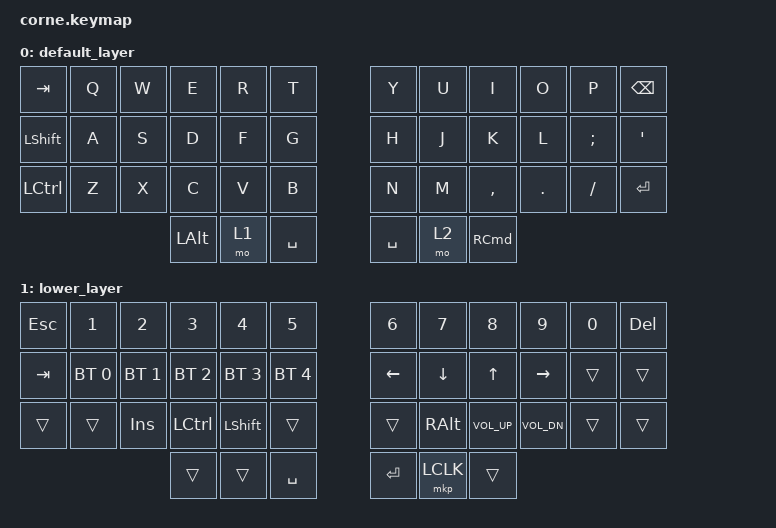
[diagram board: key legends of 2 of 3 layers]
        /*
 * Copyright (c) 2020 The ZMK Contributors
 *
 * SPDX-License-Identifier: MIT
 */

#include <dt-bindings/zmk/mouse.h>
#include <behaviors.dtsi>
#include <dt-bindings/zmk/keys.h>
#include <dt-bindings/zmk/bt.h>

/ {
        keymap {
                compatible = "zmk,keymap";

                default_layer {
                   bindings = <
// ╭─────────────────────┬─────────────────────┬────────────────────┬─────────────────────┬────────────────────┬─────────────────────╮                    ╭─────────────────────┬─────────────────────┬───────────────────┬─────────────────────┬──────────────────┬──────────────────────╮
// |        TAB          |         Q           |         W          |           E         |         R          |          T          |                    |          Y          |          U          |         I         |          O          |        P         |         BKSP         |
           &kp TAB               &kp Q                 &kp W                  &kp E               &kp R                 &kp T                                      &kp Y                 &kp U                &kp I                &kp O               &kp P               &kp BSPC
// ├─────────────────────┼─────────────────────┼────────────────────┼─────────────────────┼────────────────────┼─────────────────────┤                    ├─────────────────────┼─────────────────────┼───────────────────┼─────────────────────┼──────────────────┼──────────────────────┤
// |        SHFT         |          A          |          S         |          D          |         F          |          G          |                    |         H           |         J           |         K         |          L          |        ;         |         '            |
         &kp LSHFT               &kp A                 &kp S                 &kp D                &kp F                 &kp G                                      &kp H                 &kp J                 &kp K               &kp L              &kp SEMI             &kp SQT  
// ├─────────────────────┼─────────────────────┼────────────────────┼─────────────────────┼────────────────────┼─────────────────────┤                    ├─────────────────────┼─────────────────────┼───────────────────┼─────────────────────┼──────────────────┼──────────────────────┤
// |         CTRL        |         Z           |         X          |          C          |          V         |          B          |                    |          N          |           M         |         ,         |          .          |        /         |        ENTER         |
          &kp LCTRL              &kp Z                 &kp X                 &kp C                &kp V                &kp B                                      &kp N                  &kp M              &kp COMMA             &kp DOT             &kp FSLH              &kp RET
// ╰─────────────────────┴─────────────────────┴────────────────────┼─────────────────────┼────────────────────┼─────────────────────┤                    ├─────────────────────┼─────────────────────┼───────────────────┼─────────────────────┴──────────────────┴──────────────────────╯
//                                                                  |          ALT        |        LWR         |        SPC          |                    |        SPC          |        RES          |    HOME/Super     |
                                                                             &kp LALT             &mo 1              &kp SPACE                                   &kp SPACE              &mo 2               &kp RCMD
//                                                                  ╰─────────────────────┴────────────────────┴─────────────────────╯                    ╰─────────────────────┴─────────────────────┴───────────────────╯
                   
                        
 // &kp TAB   &kp Q &kp W &kp E &kp R &kp T               &kp Y &kp U  &kp I  &kp O  &kp P    &kp BSPC
 // &kp LCTRL &kp A &kp S &kp D &kp F &kp G               &kp H &kp J  &kp K  &kp L  &kp SEMI &kp SQT
 // &kp LSHFT &kp Z &kp X &kp C &kp V &kp B               &kp N &kp M  &kp COMMA &kp DOT &kp FSLH &kp ESC
  //                &kp LGUI &mo 1 &kp SPACE              &kp RET &mo 2 &kp RALT
                        >;
                };



                lower_layer {
                 bindings = <
// ╭─────────────────────┬─────────────────────┬────────────────────┬─────────────────────┬────────────────────┬─────────────────────╮                    ╭─────────────────────┬─────────────────────┬───────────────────┬─────────────────────┬──────────────────┬──────────────────────╮
// |          ESC        |         1           |         2          |           3         |         4          |          5          |                    |          6          |          7          |         8         |          9          |        0         |         DELET        |
            &kp ESC             &kp N1                &kp N2                 &kp N3               &kp N4               &kp N5                                     &kp N6               &kp N7                &kp N8               &kp N9              &kp N0               &kp DELETE
// ├─────────────────────┼─────────────────────┼────────────────────┼─────────────────────┼────────────────────┼─────────────────────┤                    ├─────────────────────┼─────────────────────┼───────────────────┼─────────────────────┼──────────────────┼──────────────────────┤
// |         TAB         |        BT1          |         BT2        |        BT3          |       BT4          |        BT5          |                    |         LFT         |        DWN          |        UP         |         RGT         |                  |                      |
           &kp TAB            &bt BT_SEL 0          &bt BT_SEL 1         &bt BT_SEL 2          &bt BT_SEL 3          &bt BT_SEL 4                                 &kp LEFT             &kp DOWN              &kp UP               &kp RIGHT            &trans              &trans  
// ├─────────────────────┼─────────────────────┼────────────────────┼─────────────────────┼────────────────────┼─────────────────────┤                    ├─────────────────────┼─────────────────────┼───────────────────┼─────────────────────┼──────────────────┼──────────────────────┤
// |                     |                     |       INSERT       |         CTRL        |        SHFT        |                     |                    |                     |        ALT          |       VolUp       |       VolDwn        |                  |                      |
           &trans                 &trans             &kp INS               &kp LCTRL            &kp LSHFT             &trans                                     &trans                &kp RALT            &kp C_VOL_UP         &kp C_VOL_DN           &trans              &trans
// ╰─────────────────────┴─────────────────────┴────────────────────┼─────────────────────┼────────────────────┼─────────────────────┤                    ├─────────────────────┼─────────────────────┼───────────────────┼─────────────────────┴──────────────────┴──────────────────────╯
//                                                                  |                     |                    |        SPC          |                    |       Return        |       LFTCLK        |                   |
                                                                            &trans               &trans              &kp SPACE                                    &kp RET             &mkp LCLK               &trans
//                                                                  ╰─────────────────────┴────────────────────┴─────────────────────╯                    ╰─────────────────────┴─────────────────────┴───────────────────╯
                        
  // &kp TAB    &kp N1       &kp N2       &kp N3       &kp N4       &kp N5                                 &kp N6   &kp N7   &kp N8 &kp N9    &kp N0 &kp BSPC
 //  &bt BT_CLR &bt BT_SEL 0 &bt BT_SEL 1 &bt BT_SEL 2 &bt BT_SEL 3 &bt BT_SEL 4                           &kp LEFT &kp DOWN &kp UP &kp RIGHT &trans &trans
 //  &kp LSHFT  &trans       &trans       &trans       &trans       &trans                                 &trans   &trans   &trans &trans    &trans &trans
   //                                 &kp LGUI     &trans       &kp SPACE                                  &kp RET  &trans   &kp RALT
//BTCLR-->> &bt BT_CLR 
// BT1-->> &bt BT_SEL 0
//BT2-->> &bt BT_SEL 1 etc
                        >;
                };



                raise_layer {
                 bindings = <
// ╭─────────────────────┬─────────────────────┬────────────────────┬─────────────────────┬────────────────────┬─────────────────────╮                    ╭─────────────────────┬─────────────────────┬───────────────────┬─────────────────────┬──────────────────┬──────────────────────╮
// |                     |         !           |         @          |           #         |         $          |          %          |                    |          ^          |          &          |         *         |          (          |        )         |                      |
          &trans                &kp EXCL               &kp AT                &kp HASH            &kp DLLR              &kp PRCNT                                   &kp CARET            &kp AMPS          &kp KP_MULTIPLY         &kp LPAR            &kp RPAR             &trans
// ├─────────────────────┼─────────────────────┼────────────────────┼─────────────────────┼────────────────────┼─────────────────────┤                    ├─────────────────────┼─────────────────────┼───────────────────┼─────────────────────┼──────────────────┼──────────────────────┤
// |        SHFT         |       CapsLock      |                    |        PrintSc      |                    |                     |                    |         -           |         =           |         [         |          ]          |        \         |         `            |
          &kp LSHFT              &kp CAPS              &trans               &kp PSCRN            &trans                &trans                                    &kp MINUS            &kp EQUAL              &kp LBKT            &kp RBKT             &kp BSLH            &kp GRAVE  
// ├─────────────────────┼─────────────────────┼────────────────────┼─────────────────────┼────────────────────┼─────────────────────┤                    ├─────────────────────┼─────────────────────┼───────────────────┼─────────────────────┼──────────────────┼──────────────────────┤
// |         CTRL        |                     |                    |        INSERT       |                    |                     |                    |          _          |           +         |         {         |          }          |        "|"       |          ~           |
           &kp LCTRL            &trans                 &trans                &kp INS             &trans               &trans                                      &kp UNDER             &kp PLUS            &kp LBRC             &kp RBRC             &kp PIPE            &kp TILDE
// ╰─────────────────────┴─────────────────────┴────────────────────┼─────────────────────┼────────────────────┼─────────────────────┤                    ├─────────────────────┼─────────────────────┼───────────────────┼─────────────────────┴──────────────────┴──────────────────────╯
//                                                                  |          GUI        |       SHFT         |        SPC          |                    |        SPC          |                     |     HOME/Super    |
                                                                           //&kp LGUI           &kp LSHFT            &kp SPACE                                   &kp SPACE              &trans              &kp RCMD
//                                                                  ╰─────────────────────┴────────────────────┴─────────────────────╯                    ╰─────────────────────┴─────────────────────┴───────────────────╯
                    
                        
  // &kp  TAB  &kp EXCL &kp AT &kp HASH &kp DLLR &kp PRCNT                 &kp CARET &kp AMPS  &kp KP_MULTIPLY &kp LPAR &kp RPAR &kp BSPC
  // &kp LCTRL &trans   &trans &trans   &trans   &trans                    &kp MINUS &kp EQUAL &kp LBKT  &kp RBKT &kp BSLH &kp GRAVE
  // &kp LSHFT &trans   &trans &trans   &trans   &trans                    &kp UNDER &kp PLUS  &kp LBRC  &kp RBRC &kp PIPE &kp TILDE
   //                          &kp LGUI &trans   &kp SPACE                 &kp RET   &trans    &kp RALT
                        >;
                };
        };
};
